AUTOSAR XML (schema 4-0-3)
package /ComponentTypes
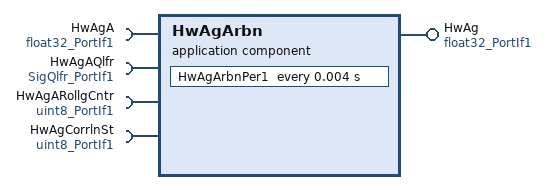
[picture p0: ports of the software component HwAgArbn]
  application sw component type HwAgArbn
    provide port HwAg: nonqueued-sender-com-spec{data-element=Val, init-value=0}, provided-interface=float32_PortIf1
    4 x require port:
      HwAgA: nonqueued-receiver-com-spec{data-element=Val, filter=data-filter-type=ALWAYS, init-value=0}, required-interface=float32_PortIf1
      HwAgAQlfr: nonqueued-receiver-com-spec{data-element=Val, filter=data-filter-type=ALWAYS, init-value=0}, required-interface=SigQlfr_PortIf1
      HwAgARollgCntr: nonqueued-receiver-com-spec{data-element=Val, filter=data-filter-type=ALWAYS, init-value=0}, required-interface=uint8_PortIf1
      HwAgCorrlnSt: nonqueued-receiver-com-spec{data-element=Val, filter=data-filter-type=ALWAYS, init-value=1}, required-interface=uint8_PortIf1
    behavior HwAgArbn_InternalBehavior
      ar-typed-per-instance-memorys:
        4 x data, all with sw-calibration-access=READ-ONLY:
          dHwAgArbnAgAAvl: type=boolean
          HwAgARollgCntrPrev: type=uint8
          HwAgAStallCntrPrev: type=uint8
          HwAgPrev: type=float32
      timing event TMT_HwAgArbnPer1: start-on-event=HwAgArbnPer1, period=0.004
      runnable HwAgArbnPer1
        data-receive-point-by-arguments:
          4 x access:
            REC_HwAgA_Val: accessed-variable=HwAgA.Val
            REC_HwAgAQlfr_Val: accessed-variable=HwAgAQlfr.Val
            REC_HwAgARollgCntr_Val: accessed-variable=HwAgARollgCntr.Val
            REC_HwAgCorrlnSt_Val: accessed-variable=HwAgCorrlnSt.Val
        data-send-points:
          access SEND_HwAg_Val: accessed-variable=HwAg.Val
  swc implementation HwAgArbn_Implementation: behavior=HwAgArbn_InternalBehavior
    code-descriptors:
      code Default: artifact-descriptors=autosar-engineering-object={short-label=Default, category=SWSRC}
